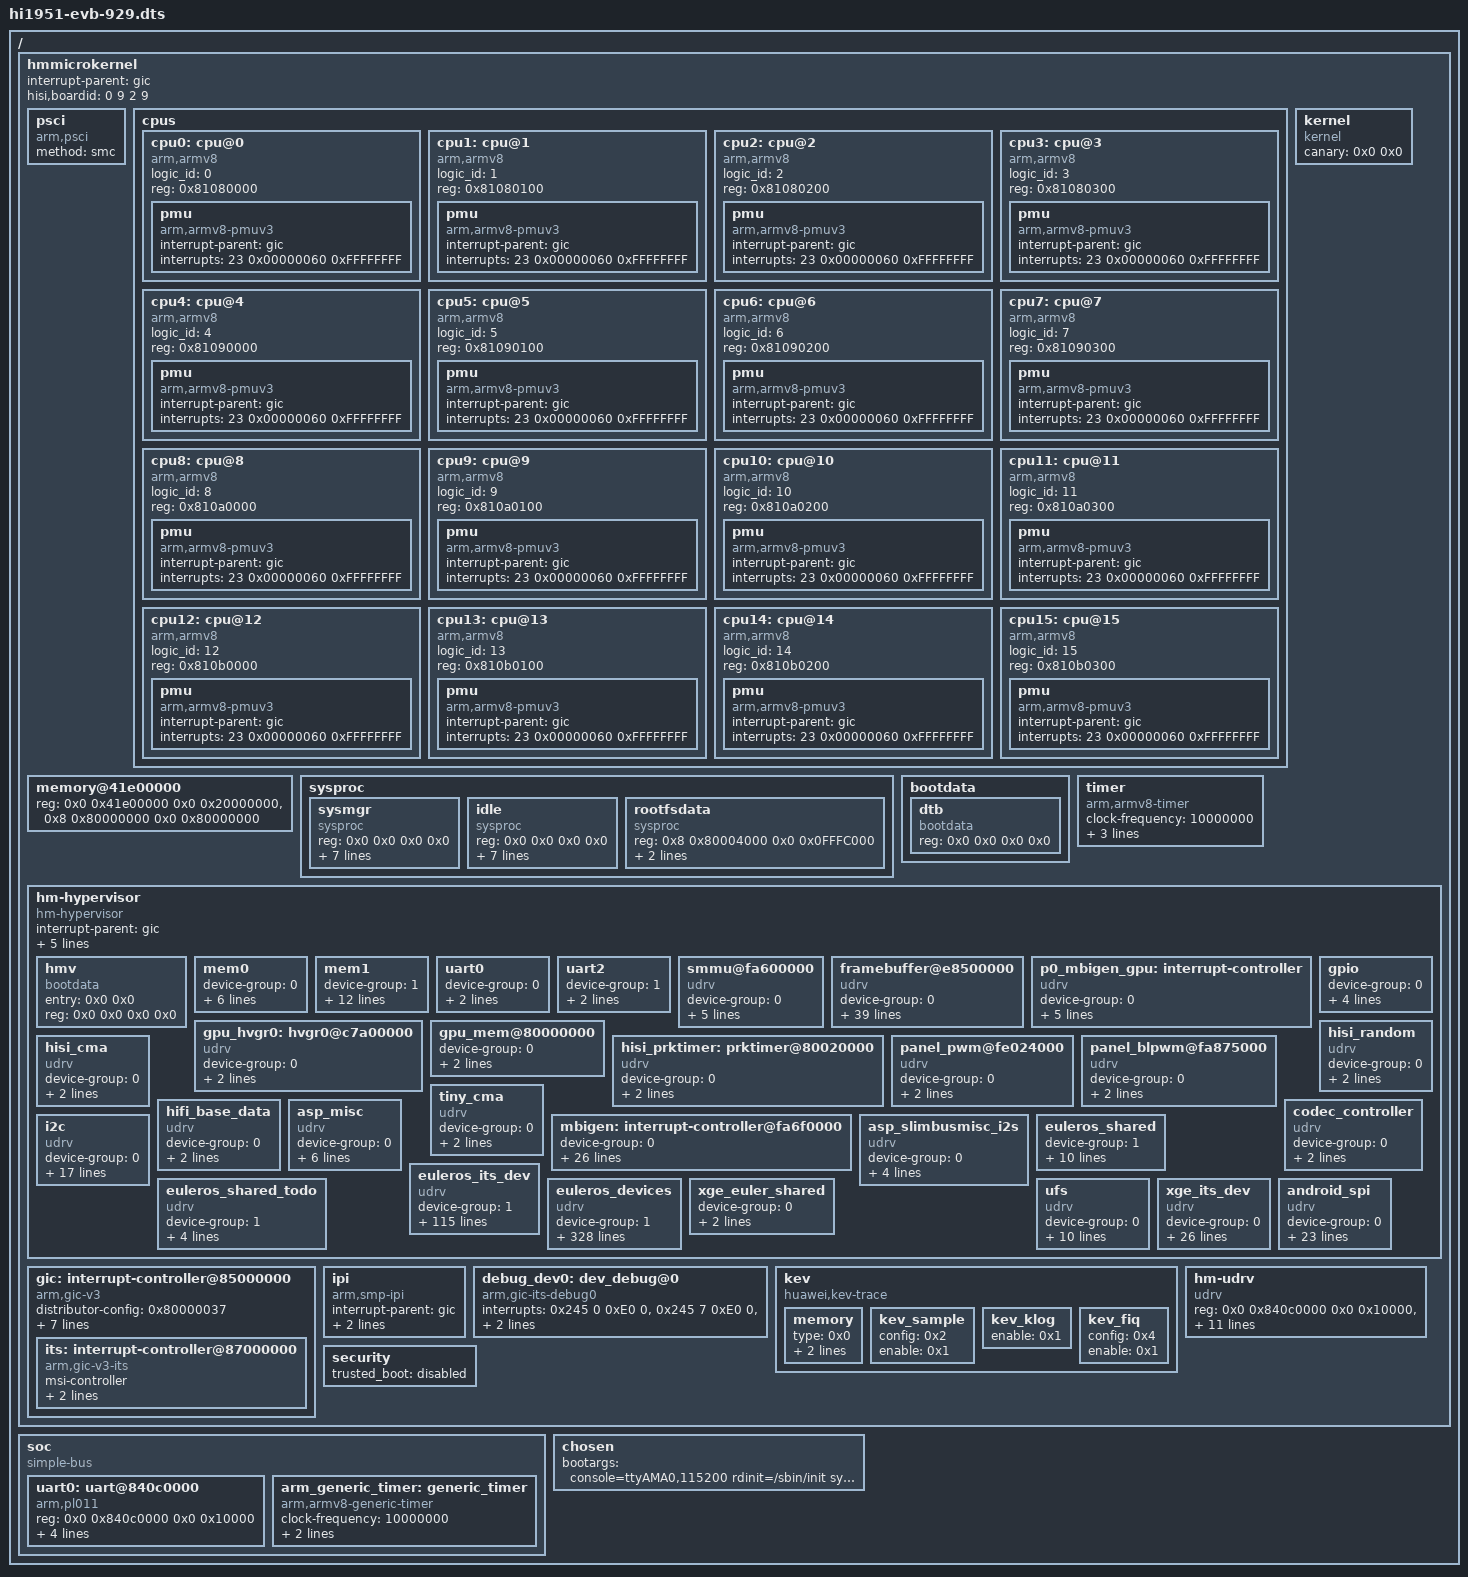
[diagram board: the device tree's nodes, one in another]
/dts-v1/;
/ { #address-cells = <2>; #size-cells = <2>; hmmicrokernel {
	interrupt-parent = <&gic>;
	hisi,boardid = <0 9 2 9>;
	#address-cells = <2>;
	#size-cells = <2>;

	psci {
		compatible = "arm,psci";
		method = "smc";
	};

	cpus {
		#address-cells = <1>;
		#size-cells = <0>;
		cpu0: cpu@0 {
			compatible = "arm,armv8";
			device_type = "cpu";
			logic_id = <0>;
			reg = <0x81080000>;
			pmu {
				compatible = "arm,armv8-pmuv3";
				interrupt-parent = <&gic>;
				/* PPI 23: PMUIRQ, level triggered, hwprio:0x60 */
				interrupts = <23 0x00000060 0xFFFFFFFF>;
			};
		};

		cpu1: cpu@1 {
			compatible = "arm,armv8";
			device_type = "cpu";
			logic_id = <1>;
			reg = <0x81080100>;
			pmu {
				compatible = "arm,armv8-pmuv3";
				interrupt-parent = <&gic>;
				/* PPI 23: PMUIRQ, level triggered, hwprio:0x60 */
				interrupts = <23 0x00000060 0xFFFFFFFF>;
			};
		};

		cpu2: cpu@2 {
			compatible = "arm,armv8";
			device_type = "cpu";
			logic_id = <2>;
			reg = <0x81080200>;
			pmu {
				compatible = "arm,armv8-pmuv3";
				interrupt-parent = <&gic>;
				/* PPI 23: PMUIRQ, level triggered, hwprio:0x60 */
				interrupts = <23 0x00000060 0xFFFFFFFF>;
			};
		};

		cpu3: cpu@3 {
			compatible = "arm,armv8";
			device_type = "cpu";
			logic_id = <3>;
			reg = <0x81080300>;
			pmu {
				compatible = "arm,armv8-pmuv3";
				interrupt-parent = <&gic>;
				/* PPI 23: PMUIRQ, level triggered, hwprio:0x60 */
				interrupts = <23 0x00000060 0xFFFFFFFF>;
			};
		};

		cpu4: cpu@4 {
			compatible = "arm,armv8";
			device_type = "cpu";
			logic_id = <4>;
			reg = <0x81090000>;
			pmu {
				compatible = "arm,armv8-pmuv3";
				interrupt-parent = <&gic>;
				/* PPI 23: PMUIRQ, level triggered, hwprio:0x60 */
				interrupts = <23 0x00000060 0xFFFFFFFF>;
			};
		};

		cpu5: cpu@5 {
			compatible = "arm,armv8";
			device_type = "cpu";
			logic_id = <5>;
			reg = <0x81090100>;
			pmu {
				compatible = "arm,armv8-pmuv3";
				interrupt-parent = <&gic>;
				/* PPI 23: PMUIRQ, level triggered, hwprio:0x60 */
				interrupts = <23 0x00000060 0xFFFFFFFF>;
			};
		};

		cpu6: cpu@6 {
			compatible = "arm,armv8";
			device_type = "cpu";
			logic_id = <6>;
			reg = <0x81090200>;
			pmu {
				compatible = "arm,armv8-pmuv3";
				interrupt-parent = <&gic>;
				/* PPI 23: PMUIRQ, level triggered, hwprio:0x60 */
				interrupts = <23 0x00000060 0xFFFFFFFF>;
			};
		};

		cpu7: cpu@7 {
			compatible = "arm,armv8";
			device_type = "cpu";
			logic_id = <7>;
			reg = <0x81090300>;
			pmu {
				compatible = "arm,armv8-pmuv3";
				interrupt-parent = <&gic>;
				/* PPI 23: PMUIRQ, level triggered, hwprio:0x60 */
				interrupts = <23 0x00000060 0xFFFFFFFF>;
			};
		};

		cpu8: cpu@8 {
			compatible = "arm,armv8";
			device_type = "cpu";
			logic_id = <8>;
			reg = <0x810a0000>;
			pmu {
				compatible = "arm,armv8-pmuv3";
				interrupt-parent = <&gic>;
				/* PPI 23: PMUIRQ, level triggered, hwprio:0x60 */
				interrupts = <23 0x00000060 0xFFFFFFFF>;
			};
		};

		cpu9: cpu@9 {
			compatible = "arm,armv8";
			device_type = "cpu";
			logic_id = <9>;
			reg = <0x810a0100>;
			pmu {
				compatible = "arm,armv8-pmuv3";
				interrupt-parent = <&gic>;
				/* PPI 23: PMUIRQ, level triggered, hwprio:0x60 */
				interrupts = <23 0x00000060 0xFFFFFFFF>;
			};
		};

		cpu10: cpu@10 {
			compatible = "arm,armv8";
			device_type = "cpu";
			logic_id = <10>;
			reg = <0x810a0200>;
			pmu {
				compatible = "arm,armv8-pmuv3";
				interrupt-parent = <&gic>;
				/* PPI 23: PMUIRQ, level triggered, hwprio:0x60 */
				interrupts = <23 0x00000060 0xFFFFFFFF>;
			};
		};

		cpu11: cpu@11 {
			compatible = "arm,armv8";
			device_type = "cpu";
			logic_id = <11>;
			reg = <0x810a0300>;
			pmu {
				compatible = "arm,armv8-pmuv3";
				interrupt-parent = <&gic>;
				/* PPI 23: PMUIRQ, level triggered, hwprio:0x60 */
				interrupts = <23 0x00000060 0xFFFFFFFF>;
			};
		};

		cpu12: cpu@12 {
			compatible = "arm,armv8";
			device_type = "cpu";
			logic_id = <12>;
			reg = <0x810b0000>;
			pmu {
				compatible = "arm,armv8-pmuv3";
				interrupt-parent = <&gic>;
				/* PPI 23: PMUIRQ, level triggered, hwprio:0x60 */
				interrupts = <23 0x00000060 0xFFFFFFFF>;
			};
		};

		cpu13: cpu@13 {
			compatible = "arm,armv8";
			device_type = "cpu";
			logic_id = <13>;
			reg = <0x810b0100>;
			pmu {
				compatible = "arm,armv8-pmuv3";
				interrupt-parent = <&gic>;
				/* PPI 23: PMUIRQ, level triggered, hwprio:0x60 */
				interrupts = <23 0x00000060 0xFFFFFFFF>;
			};
		};

		cpu14: cpu@14 {
			compatible = "arm,armv8";
			device_type = "cpu";
			logic_id = <14>;
			reg = <0x810b0200>;
			pmu {
				compatible = "arm,armv8-pmuv3";
				interrupt-parent = <&gic>;
				/* PPI 23: PMUIRQ, level triggered, hwprio:0x60 */
				interrupts = <23 0x00000060 0xFFFFFFFF>;
			};
		};

		cpu15: cpu@15 {
			compatible = "arm,armv8";
			device_type = "cpu";
			logic_id = <15>;
			reg = <0x810b0300>;
			pmu {
				compatible = "arm,armv8-pmuv3";
				interrupt-parent = <&gic>;
				/* PPI 23: PMUIRQ, level triggered, hwprio:0x60 */
				interrupts = <23 0x00000060 0xFFFFFFFF>;
			};
		};
	};

	memory@41e00000 {
		device_type = "memory";
		reg = <0x0 0x41e00000 0x0 0x20000000>,
		      <0x8 0x80000000 0x0 0x80000000>;
	};

	sysproc {
		#address-cells = <2>;
		#size-cells = <2>;
		sysmgr {
			compatible = "sysproc", "sysmgr";
			/* filled by bootloader */
			reg      = <0x0 0x0 0x0 0x0>;
			vphdr    = <0x0 0x0>;
			ventry   = <0x0 0x0>;
			pvoffset = <0x0 0x0>;
			nphdrs   = <0>;
			stack_start = <0x0 0x0>;
			stack_end = <0x0 0x0>;
			canary = <0x0 0x0>;
		};
		idle {
			compatible = "sysproc", "idle";
			/* filled by bootloader */
			reg      = <0x0 0x0 0x0 0x0>;
			vphdr    = <0x0 0x0>;
			ventry   = <0x0 0x0>;
			pvoffset = <0x0 0x0>;
			nphdrs   = <0>;
			stack_start = <0x0 0x0>;
			stack_end = <0x0 0x0>;
			canary = <0x0 0x0>;
		};

		rootfsdata {
			compatible = "sysproc", "rootfs";
			reg = <0x8 0x80004000 0x0 0x0FFFC000>;
			ventry = <0x0 0x0>;
			/* filled by bootloader */
			pvoffset = <0x0 0x0>;
		};
	};

	kernel {
		compatible = "kernel";
		/* filled by bootloader */
		canary = <0x0 0x0>;
	};

	bootdata {
		#address-cells = <2>;
		#size-cells = <2>;
		dtb {
			compatible = "bootdata", "dtb";
			/* filled by bootloader */
			reg = <0x0 0x0 0x0 0x0>;
		};
	};

	timer {
		compatible = "arm,armv8-timer";
		clock-frequency = <10000000>;
		/* interrupt settings */
		interrupt-parent = <&gic>;

		/* PPI 30: Non-secure physical timer
		 * level triggered, only cpu0, hwprio:0x60 */
		interrupts = <30 0x00000060 0xFFFFFFFF>,
			     <26 0x00000060 0xFFFFFFFF>;
	};

	hm-hypervisor {
		compatible = "hm-hypervisor";
		#address-cells = <2>;
		#size-cells = <2>;

		interrupt-parent = <&gic>;
		interrupts = <15 0x00000060 0xFFFFFFFF>,
			     <25 0x00000060 0xFFFFFFFF>,
			     <27 0x00000060 0xFFFFFFFF>;

		virtual-timer-irq = <27>;
		vgic-base-address = <0x7F 0xFF000000>;

		hmv {
			compatible = "bootdata";
			/* filled by bootloader */
			entry = <0x0 0x0>;
			reg = <0x0 0x0 0x0 0x0>;
		};

		mem0 {
			device-group = <0>;
			normal-mem;
			uvmm-access;
			reg = <0x9 0x00000000 0x0 0x0FFF0000>,
			      <0x9 0x10000000 0x0 0x6C000000>;
			map = <0x0 0x00000000 0x0 0x0FFF0000>,
			      <0x9 0x10000000 0x0 0x6C000000>;
		};

		mem1 {
			device-group = <1>;
			normal-mem;
			uvmm-access;
			reg = <0xA 0x00000000 0x0 0x0FFF0000>,
			      <0xA 0x10000000 0x1 0xf0000000>,
			      <0x0 0x0B101000 0x0 0x001FF000>, //log_redirect
			      <0x0 0x61E00000 0x0 0x10000000>, //cma GPA: 0x6bc00000
			      <0x9 0x10000000 0x0 0x6C000000>;
			map = <0xA 0x00000000 0x0 0x0FFF0000>,
			      <0xA 0x10000000 0x1 0xf0000000>,
			      <0x0 0x0B101000 0x0 0x001FF000>, //log_redirect
			      <0x0 0x61E00000 0x0 0x10000000>, //cma GPA: 0x6bc00000
			      <0x9 0x10000000 0x0 0x6C000000>;
		};

		uart0 {
			device-group = <0>;
			reg = <0x00 0x840c0000 0x0 0x00010000>;
			map = <0x7F 0xFE000000 0x0 0x00010000>;
		};

		uart2 {
			device-group = <1>;
			reg = <0x00 0x840c0000 0x0 0x00010000>;
			map = <0x7F 0xFE000000 0x0 0x00010000>;
		};

		smmu@fa600000 {
			device-group = <0>;
			compatible = "udrv";
			msi-parent = <&its>;
			interrupts = <0x7f41 0 0xE0 0>,
				     <0x7f41 1 0xE0 0>,
				     <0x7f41 2 0xE0 0>,
				     <0x7f41 3 0xE0 0>;
			reg = <0x0 0xfa600000 0x0 0x40000>;
			map = <0x0 0xfa600000 0x0 0x40000>;
		};

		framebuffer@e8500000 {
			device-group = <0>;
			compatible = "udrv";
			interrupt-parent = <&gic>;
			interrupts = <277 0x000000E0 0xFFFFFFFF>,
				     <278 0x000000E0 0xFFFFFFFF>,
				     <279 0x000000E0 0xFFFFFFFF>,
				     <283 0x000000E0 0xFFFFFFFF>,
				     <284 0x000000E0 0xFFFFFFFF>,
				     <363 0x000000E0 0xFFFFFFFF>,
				     <319 0x000000E0 0xFFFFFFFF>,
				     <388 0x000000E0 0xFFFFFFFF>,
				     <316 0x000000E0 0xFFFFFFFF>,
				     <317 0x000000E0 0xFFFFFFFF>,
				     <318 0x000000E0 0xFFFFFFFF>,
				     <322 0x000000E0 0xFFFFFFFF>;
			reg = <0x0 0xe8500000 0x0 0x000a0000>,
			      <0x0 0xe8601000 0x0 0x00001000>,
			      <0x0 0xe8680000 0x0 0x00010000>,
			      <0x0 0xe8820000 0x0 0x00001000>,
			      <0x0 0xf8481000 0x0 0x00001000>,
			      <0x0 0xf8500000 0x0 0x00080000>,
			      <0x0 0xf8581000 0x0 0x00001000>,
			      <0x0 0xfa670000 0x0 0x00010000>,
			      <0x0 0xfa700000 0x0 0x00100000>,
			      <0x0 0xfa89b000 0x0 0x00001000>,
			      <0x0 0xffa2e000 0x0 0x00001000>,
			      <0x0 0xfff01000 0x0 0x00001000>,
			      <0x0 0xfff05000 0x0 0x00001000>;
			map = <0x0 0xe8500000 0x0 0x000a0000>,
			      <0x0 0xe8601000 0x0 0x00001000>,
			      <0x0 0xe8680000 0x0 0x00010000>,
			      <0x0 0xe8820000 0x0 0x00001000>,
			      <0x0 0xf8481000 0x0 0x00001000>,
			      <0x0 0xf8500000 0x0 0x00080000>,
			      <0x0 0xf8581000 0x0 0x00001000>,
			      <0x0 0xfa670000 0x0 0x00010000>,
			      <0x0 0xfa700000 0x0 0x00100000>,
			      <0x0 0xfa89b000 0x0 0x00001000>,
			      <0x0 0xffa2e000 0x0 0x00001000>,
			      <0x0 0xfff01000 0x0 0x00001000>,
			      <0x0 0xfff05000 0x0 0x00001000>;
		};

		p0_mbigen_gpu: interrupt-controller {
			device-group = <0>;
			compatible = "udrv";
			msi-parent = <&its>;
			interrupts = <0x7f94 0 0xE0 0>,
				     <0x7f94 1 0xE0 0>,
				     <0x7f94 2 0xE0 0>,
				     <0x7f94 3 0xE0 0>;
			reg = <0x0 0xc7800000 0x0 0x100000>;
			map = <0x0 0xc7800000 0x0 0x100000>;
		};

		gpu_hvgr0: hvgr0@c7a00000 {
			device-group = <0>;
			compatible = "udrv";
			reg = <0x0 0xc7a00000 0x0 0x10000>;
			map = <0x0 0xc7a00000 0x0 0x10000>;
		};

		gpu_mem@80000000 {
			device-group = <0>;
			reg = <0x0 0x80000000 0x0 0x10000>;
			map = <0x0 0x80000000 0x0 0x10000>;
		};

		hisi_prktimer: prktimer@80020000 {
			device-group = <0>;
			compatible = "udrv";
			reg = <0x0 0x80020000 0x0 0x10000>;
			map = <0x0 0x80020000 0x0 0x10000>;
		};

		panel_pwm@fe024000 {
			device-group = <0>;
			compatible = "udrv";
			reg = <0x0 0xfe024000 0x0 0x1000>;
			map = <0x0 0xfe024000 0x0 0x1000>;
		};

		panel_blpwm@fa875000 {
			device-group = <0>;
			compatible = "udrv";
			reg = <0x0 0xfa875000 0x0 0x1000>;
			map = <0x0 0xfa875000 0x0 0x1000>;
		};

		gpio {
			device-group = <0>;
			reg = <0x0 0xfa6b0000 0x0 0x10000>,
			      <0x0 0x840f0000 0x0 0x10000>;
			map = <0x0 0xfa6b0000 0x0 0x10000>,
			      <0x0 0x840f0000 0x0 0x10000>;
		};

		hisi_random {
			device-group = <0>;
			compatible = "udrv";
			reg = <0x0 0x11593000 0x0 0x01000>;
			map = <0x0 0x11593000 0x0 0x01000>;
		};

		hisi_cma {
			device-group = <0>;
			compatible = "udrv";
			reg = <0x9 0x90000000 0x0 0x10000000>;
			map = <0x0 0x61E00000 0x0 0x10000000>;
		};

		tiny_cma {
			device-group = <0>;
			compatible = "udrv";
			reg = <0x9 0xa0000000 0x0 0x04000000>;
			map = <0x0 0x71E00000 0x0 0x04000000>;
		};

		hifi_base_data: hifi_base_data {
			device-group = <0>;
			compatible = "udrv";
			reg = <0x0 0x29800000 0x0 0x01500000>;
			map = <0x0 0x29800000 0x0 0x01500000>;
		};

		mbigen: interrupt-controller@fa6f0000 {
			device-group = <0>;
			msi-parent = <&its>;
			interrupts = <0x7f80 0 0xE0 0>, <0x7f80 1 0xE0 0>,
				     <0x7f80 2 0xE0 0>, <0x7f80 3 0xE0 0>,
				     <0x7f80 4 0xE0 0>, <0x7f80 5 0xE0 0>,
				     <0x7f81 0 0xE0 0>, <0x7f81 1 0xE0 0>,
				     <0x7f82 0 0xE0 0>, <0x7f82 1 0xE0 0>,
				     <0x7f83 0 0xE0 0>, <0x7f83 1 0xE0 0>,
				     <0x7f90 0 0xE0 0>, <0x7f90 1 0xE0 0>,
				     <0x7f90 2 0xE0 0>, <0x7f90 3 0xE0 0>,
				     <0x7f90 4 0xE0 0>, <0x7f90 5 0xE0 0>,
				     <0x7f90 6 0xE0 0>, <0x7f90 7 0xE0 0>,
				     <0x7f90 8 0xE0 0>, <0x7f90 9 0xE0 0>,
				     <0x7f90 10 0xE0 0>, <0x7f90 11 0xE0 0>,
				     <0x7f90 12 0xE0 0>, <0x7f90 13 0xE0 0>,
				     <0x7f90 14 0xE0 0>, <0x7f90 15 0xE0 0>,
				     <0x7f90 16 0xE0 0>, <0x7f90 17 0xE0 0>,
				     <0x7f90 18 0xE0 0>, <0x7f90 19 0xE0 0>,
				     <0x7f90 20 0xE0 0>, <0x7f90 21 0xE0 0>,
				     <0x7f90 22 0xE0 0>, <0x7f90 23 0xE0 0>,
				     <0x7f90 24 0xE0 0>, <0x7f90 25 0xE0 0>,
				     <0x7f90 26 0xE0 0>, <0x7f90 27 0xE0 0>,
				     <0x7f90 28 0xE0 0>, <0x7f90 29 0xE0 0>,
				     <0x7f90 30 0xE0 0>, <0x7f90 31 0xE0 0>,
				     <0x7fab 32 0xE0 0>, <0x7fab 33 0xE0 0>;
			reg = <0x0 0xfa6f0000 0x0 0x10000>;
			map = <0x0 0xfa6f0000 0x0 0x10000>;
		};

		codec_controller: codec_controller {
			device-group = <0>;
			compatible = "udrv";
			reg = <0x0 0xffb04000 0x0 0x1000>;
			map = <0x0 0xffb04000 0x0 0x1000>;
		};

		asp_misc: asp_misc {
			device-group = <0>;
			compatible = "udrv";
			reg = <0x0 0xfa680000 0x0 0x7000>,
			      <0x0 0xfa6c0000 0x0 0x10000>,
			      <0x0 0xfa660000 0x0 0x4000>;
			map = <0x0 0xfa680000 0x0 0x7000>,
			      <0x0 0xfa6c0000 0x0 0x10000>,
			      <0x0 0xfa660000 0x0 0x4000>;
		};

		asp_slimbusmisc_i2s: asp_slimbusmisc_i2s {
			device-group = <0>;
			compatible = "udrv";
			interrupt-parent = <&gic>;
			interrupts = <182 0x000000E0 0xFFFFFFFF>;
			reg = <0x0 0xfa400000 0x0 0x1c0000>;
			map = <0x0 0xfa400000 0x0 0x1c0000>;
		};

		i2c {
			device-group = <0>;
			compatible = "udrv";
			interrupt-parent = <&gic>;
			interrupts = < 88 0x000000E0 0xFFFFFFFF>,
				     <218 0x000000E0 0xFFFFFFFF>,
				     <219 0x000000E0 0xFFFFFFFF>,
				     <220 0x000000E0 0xFFFFFFFF>,
				     <288 0x000000E0 0xFFFFFFFF>,
				     <289 0x000000E0 0xFFFFFFFF>,
				     <361 0x000000E0 0xFFFFFFFF>,
				     < 85 0x000000E0 0xFFFFFFFF>;
			reg = <0x0 0x8b0c0000 0x0 0x10000>,
			      <0x0 0x84040000 0x0 0x40000>,
			      <0x0 0xa2180000 0x0 0x20000>,
			      <0x0 0xfa690000 0x0 0x10000>;
			map = <0x0 0x8b0c0000 0x0 0x10000>,
			      <0x0 0x84040000 0x0 0x40000>,
			      <0x0 0xa2180000 0x0 0x20000>,
			      <0x0 0xfa690000 0x0 0x10000>;
		};

		euleros_shared {
			device-group = <1>;
			reg = <0x0 0x80000000 0x0 0x00010000>, //rdr_ap_adapter rdr_spmi mttcan2 mttcan3 mttcan4
			      <0x0 0xa4510000 0x0 0x00001000>, //udrv gpio1
			      <0x0 0x840f0000 0x0 0x00010000>, //gpio
			      <0x0 0xfa6b0000 0x0 0x00010000>, //gpio3
			      <0x0 0xfa6f0000 0x0 0x00010000>; //mbigen
			map = <0x0 0x80000000 0x0 0x00010000>, //rdr_ap_adapter rdr_spmi mttcan2 mttcan3 mttcan4
			      <0x0 0xa4510000 0x0 0x00001000>, //udrv gpio1
			      <0x0 0x840f0000 0x0 0x00010000>, //gpio
			      <0x0 0xfa6b0000 0x0 0x00010000>, //gpio3
			      <0x0 0xfa6f0000 0x0 0x00010000>; //mbigen
		};

		euleros_shared_todo {
			device-group = <1>;
			compatible = "udrv";
			reg = <0xc 0x00000000 0x0 0x20000000>, //runtime test case
			      <0xc 0x60000000 0x0 0x40000000>; //acl test case
			map = <0xc 0x00000000 0x0 0x20000000>, //runtime test case
			      <0xc 0x60000000 0x0 0x40000000>; //acl test case
		};

		euleros_its_dev {
			device-group = <1>;
			compatible = "udrv";
			msi-parent = <&its>;

			interrupts =	<0x7400 0xff 0xE0 0>,//pcie
					<0x7b00 0x00 0xE0 0>,//pcie dma
					<0x7b00 0x1f 0xE0 0>,//pcie dma
					<0x7b08 0x00 0xE0 0>,//doorbell
					<0x7b08 0x1c 0xE0 0>,//doorbell
					<0x7f1b 0x00 0xE0 0>,//mmu
					<0x7f1b 0xff 0xE0 0>,//mmu
					<0x7f20 0x00 0xE0 0>,//925 peri_smmu
					<0x7f20 0x01 0xE0 0>,//dvpp
					<0x7f21 0x00 0xE0 0>,//dvpp
					<0x7f21 0x01 0xE0 0>,//dvpp
					<0x7f22 0x00 0xE0 0>,//dvpp
					<0x7f22 0x01 0xE0 0>,//dvpp
					<0x7f23 0x00 0xE0 0>,//dvpp/dsmmu0
					<0x7f23 0x01 0xE0 0>,//dvpp/dsmmu0
					<0x7f24 0x00 0xE0 0>,//dvpp
					<0x7f24 0x01 0xE0 0>,//dvpp
					<0x7f25 0x00 0xE0 0>,//dvpp
					<0x7f25 0x01 0xE0 0>,//dvpp
					<0x7f26 0x00 0xE0 0>,//mmu
					<0x7f26 0x01 0xE0 0>,//mmu
					<0x7f27 0x00 0xE0 0>,//mmu
					<0x7f27 0x01 0xE0 0>,//mmu
					<0x7f28 0x00 0xE0 0>,//mmu
					<0x7f28 0x01 0xE0 0>,//mmu
					<0x7f29 0x00 0xE0 0>,//mmu
					<0x7f29 0x01 0xE0 0>,//mmu
					<0x7f2a 0x00 0xE0 0>,//mmu
					<0x7f2a 0x01 0xE0 0>,//mmu
					<0x7f2b 0x00 0xE0 0>,//mmu
					<0x7f2b 0x01 0xE0 0>,//mmu
					<0x7f2c 0x00 0xE0 0>,//mmu
					<0x7f2c 0x01 0xE0 0>,//mmu
					<0x7f2d 0x00 0xE0 0>,//mmu
					<0x7f2d 0x01 0xE0 0>,//mmu
					<0x7f2e 0x00 0xE0 0>,//mmu
					<0x7f2e 0x01 0xE0 0>,//mmu
					<0x7f2f 0x00 0xE0 0>,//mmu
					<0x7f2f 0x01 0xE0 0>,//mmu
					<0x7f30 0x00 0xE0 0>,//mmu
					<0x7f30 0x01 0xE0 0>,//mmu
					<0x7f31 0x00 0xE0 0>,//mmu
					<0x7f31 0x01 0xE0 0>,//mmu
					<0x7f38 0x00 0xE0 0>,//mmu
					<0x7f38 0x01 0xE0 0>,//mmu
					<0x7f39 0x00 0xE0 0>,//mmu
					<0x7f39 0x01 0xE0 0>,//mmu
					<0x7f3a 0x00 0xE0 0>,//mmu
					<0x7f3a 0x01 0xE0 0>,//mmu
					<0x7f3b 0x00 0xE0 0>,//mmu
					<0x7f3b 0x01 0xE0 0>,//mmu
					<0x7f3c 0x00 0xE0 0>,//mmu
					<0x7f3c 0x01 0xE0 0>,//mmu
					<0x7f3d 0x00 0xE0 0>,//mmu
					<0x7f3d 0x01 0xE0 0>,//mmu
					<0x7f3e 0x00 0xE0 0>,//mmu
					<0x7f3e 0x01 0xE0 0>,//mmu
					<0x7f3f 0x00 0xE0 0>,//mmu
					<0x7f3f 0x01 0xE0 0>,//mmu
					<0x7f40 0x00 0xE0 0>,//mmu
					<0x7f40 0x01 0xE0 0>,//mmu
					<0x7f45 0x00 0xE0 0>,//mmu
					<0x7f45 0xff 0xE0 0>,//mmu
					<0x7f46 0x00 0xE0 0>,//mmu
					<0x7f46 0x01 0xE0 0>,//mmu
					<0x7f49 0x00 0xE0 0>,//dvpp_smmu0
					<0x7f49 0x01 0xE0 0>,//dvpp_smmu0
					<0x7f58 0x00 0xE0 0>,//mbigen_vdec
					<0x7f58 0xff 0xE0 0>,//mbigen_vdec
					<0x7f5d 0x00 0xE0 0>,//mbigen_jpegd
					<0x7f5d 0xff 0xE0 0>,//mbigen_jpegd
					<0x7f5f 0x00 0xE0 0>,//mbigen_jpege
					<0x7f5f 0xff 0xE0 0>,//mbigen_jpege
					<0x7f77 0x00 0xE0 0>,//mbigen_vpc_err
					<0x7f77 0xff 0xE0 0>,//mbigen_vpc_err
					<0x7f91 0xff 0xE0 0>,//dvpp
					<0x7f96 0x00 0xE0 0>,//mbigen_gpio5
					<0x7f96 0x01 0xE0 0>,//mbigen_gpio5
					<0x7f96 0x02 0xE0 0>,//mbigen_gpio5
					<0x7f96 0x03 0xE0 0>,//mbigen_gpio5
					<0x7f96 0x04 0xE0 0>,//mbigen_gpio5
					<0x7f96 0x05 0xE0 0>,//mbigen_gpio5
					<0x7f96 0x06 0xE0 0>,//mbigen_gpio5
					<0x7f96 0x07 0xE0 0>,//mbigen_gpio5
					<0x7f96 0x08 0xE0 0>,//mbigen_gpio5
					<0x7f96 0x09 0xE0 0>,//mbigen_gpio5
					<0x7f96 0x0a 0xE0 0>,//mbigen_gpio5
					<0x7f96 0x0b 0xE0 0>,//mbigen_gpio5
					<0x7f96 0x0c 0xE0 0>,//mbigen_gpio5
					<0x7f96 0x0d 0xE0 0>,//mbigen_gpio5
					<0x7f96 0x0e 0xE0 0>,//mbigen_gpio5
					<0x7f96 0x0f 0xE0 0>,//mbigen_gpio5
					<0x7f96 0x10 0xE0 0>,//mbigen_gpio5
					<0x7f96 0x11 0xE0 0>,//mbigen_gpio5
					<0x7f96 0x12 0xE0 0>,//mbigen_gpio5
					<0x7f96 0x13 0xE0 0>,//mbigen_gpio5
					<0x7f96 0x14 0xE0 0>,//mbigen_gpio5
					<0x7f96 0x15 0xE0 0>,//mbigen_gpio5
					<0x7f96 0x16 0xE0 0>,//mbigen_gpio5
					<0x7f96 0x17 0xE0 0>,//mbigen_gpio5
					<0x7f96 0x18 0xE0 0>,//mbigen_gpio5
					<0x7f96 0x19 0xE0 0>,//mbigen_gpio5
					<0x7f96 0x1a 0xE0 0>,//mbigen_gpio5
					<0x7f96 0x1b 0xE0 0>,//mbigen_gpio5
					<0x7f96 0x1c 0xE0 0>,//mbigen_gpio5
					<0x7f96 0x1d 0xE0 0>,//mbigen_gpio5
					<0x7f96 0x1e 0xE0 0>,//mbigen_gpio5
					<0x7f96 0x1f 0xE0 0>,//mbigen_gpio5
					<0x7f96 0xff 0xE0 0>,//mbigen_gpio5
					<0x7f9e 0x00 0xE0 0>,//mbigen_gpio4
					<0x7f9e 0x01 0xE0 0>,//mbigen_gpio4
					<0x7f9e 0x02 0xE0 0>,//mbigen_gpio4
					<0x7f9e 0x03 0xE0 0>,//mbigen_gpio4
					<0x7f9e 0x04 0xE0 0>,//mbigen_gpio4
					<0x7f9e 0x05 0xE0 0>,//mbigen_gpio4
					<0x7f9e 0x06 0xE0 0>,//mbigen_gpio4
					<0x7f9e 0x07 0xE0 0>,//mbigen_gpio4
					<0x7f9e 0x08 0xE0 0>,//mbigen_gpio4
					<0x7f9e 0x09 0xE0 0>,//mbigen_gpio4
					<0x7f9e 0x0a 0xE0 0>,//mbigen_gpio4
					<0x7f9e 0x0b 0xE0 0>,//mbigen_gpio4
					<0x7f9e 0x0c 0xE0 0>,//mbigen_gpio4
					<0x7f9e 0x0d 0xE0 0>,//mbigen_gpio4
					<0x7f9e 0x0e 0xE0 0>,//mbigen_gpio4
					<0x7f9e 0x0f 0xE0 0>,//mbigen_gpio4
					<0x7f9e 0x10 0xE0 0>,//mbigen_gpio4
					<0x7f9e 0x11 0xE0 0>,//mbigen_gpio4
					<0x7f9e 0x12 0xE0 0>,//mbigen_gpio4
					<0x7f9e 0x13 0xE0 0>,//mbigen_gpio4
					<0x7f9e 0x14 0xE0 0>,//mbigen_gpio4
					<0x7f9e 0x15 0xE0 0>,//mbigen_gpio4
					<0x7f9e 0x16 0xE0 0>,//mbigen_gpio4
					<0x7f9e 0x17 0xE0 0>,//mbigen_gpio4
					<0x7f9e 0x18 0xE0 0>,//mbigen_gpio4
					<0x7f9e 0x19 0xE0 0>,//mbigen_gpio4
					<0x7f9e 0x1a 0xE0 0>,//mbigen_gpio4
					<0x7f9e 0x1b 0xE0 0>,//mbigen_gpio4
					<0x7f9e 0x1c 0xE0 0>,//mbigen_gpio4
					<0x7f9e 0x1d 0xE0 0>,//mbigen_gpio4
					<0x7f9e 0x1e 0xE0 0>,//mbigen_gpio4
					<0x7f9e 0x1f 0xE0 0>,//mbigen_gpio4
					<0x7f9e 0xff 0xE0 0>,//mbigen_gpio4
					<0x7faa 0x00 0xE0 0>,//mbigen_gpio7
					<0x7faa 0x01 0xE0 0>,//mbigen_gpio7
					<0x7faa 0x02 0xE0 0>,//mbigen_gpio7
					<0x7faa 0x03 0xE0 0>,//mbigen_gpio7
					<0x7faa 0x04 0xE0 0>,//mbigen_gpio7
					<0x7faa 0x05 0xE0 0>,//mbigen_gpio7
					<0x7faa 0x06 0xE0 0>,//mbigen_gpio7
					<0x7faa 0x07 0xE0 0>,//mbigen_gpio7
					<0x7fa4 0x00 0xE0 0>,//mbigen_gpio0
					<0x7fa4 0x01 0xE0 0>,//mbigen_gpio0
					<0x7fa4 0x02 0xE0 0>,//mbigen_gpio0
					<0x7fa4 0x03 0xE0 0>,//mbigen_gpio0
					<0x7fa4 0x04 0xE0 0>,//mbigen_gpio0
					<0x7fa4 0x05 0xE0 0>,//mbigen_gpio0
					<0x7fa4 0x06 0xE0 0>,//mbigen_gpio0
					<0x7fa4 0x07 0xE0 0>,//mbigen_gpio0
					<0x7fa4 0x08 0xE0 0>,//mbigen_gpio0
					<0x7fa4 0x09 0xE0 0>,//mbigen_gpio0
					<0x7fa4 0x0a 0xE0 0>,//mbigen_gpio0
					<0x7fa4 0x0b 0xE0 0>,//mbigen_gpio0
					<0x7fa4 0x0c 0xE0 0>,//mbigen_gpio0
					<0x7fa4 0x0d 0xE0 0>,//mbigen_gpio0
					<0x7fa4 0x0e 0xE0 0>,//mbigen_gpio0
					<0x7fa4 0x0f 0xE0 0>,//mbigen_gpio0
					<0x7fa4 0x10 0xE0 0>,//mbigen_gpio0
					<0x7fa4 0x11 0xE0 0>,//mbigen_gpio0
					<0x7fa4 0x12 0xE0 0>,//mbigen_gpio0
					<0x7fa4 0x13 0xE0 0>,//mbigen_gpio0
					<0x7fa4 0x14 0xE0 0>,//mbigen_gpio0
					<0x7fa4 0x15 0xE0 0>,//mbigen_gpio0
					<0x7fa4 0x16 0xE0 0>,//mbigen_gpio0
					<0x7fa4 0x17 0xE0 0>,//mbigen_gpio0
					<0x7fa4 0x18 0xE0 0>,//mbigen_gpio0
					<0x7fa4 0x19 0xE0 0>,//mbigen_gpio0
					<0x7fa4 0x1a 0xE0 0>,//mbigen_gpio0
					<0x7fa4 0x1b 0xE0 0>,//mbigen_gpio0
					<0x7fa4 0x1c 0xE0 0>,//mbigen_gpio0
					<0x7fa4 0x1d 0xE0 0>,//mbigen_gpio0
					<0x7fa4 0x1e 0xE0 0>,//mbigen_gpio0
					<0x7fa4 0x1f 0xE0 0>,//mbigen_gpio0
					<0x7fa4 0xff 0xE0 0>,//mbigen_gpio0
					<0x7fa5 0x00 0xE0 0>,//mbigen_gpio1
					<0x7fa5 0x01 0xE0 0>,//mbigen_gpio1
					<0x7fa5 0x02 0xE0 0>,//mbigen_gpio1
					<0x7fa5 0x03 0xE0 0>,//mbigen_gpio1
					<0x7fa5 0x04 0xE0 0>,//mbigen_gpio1
					<0x7fa5 0x05 0xE0 0>,//mbigen_gpio1
					<0x7fa5 0x06 0xE0 0>,//mbigen_gpio1
					<0x7fa5 0x07 0xE0 0>,//mbigen_gpio1
					<0x7fa5 0x08 0xE0 0>,//mbigen_gpio1
					<0x7fa5 0x09 0xE0 0>,//mbigen_gpio1
					<0x7fa5 0x0a 0xE0 0>,//mbigen_gpio1
					<0x7fa5 0x0b 0xE0 0>,//mbigen_gpio1
					<0x7fa5 0x0c 0xE0 0>,//mbigen_gpio1
					<0x7fa5 0x0d 0xE0 0>,//mbigen_gpio1
					<0x7fa5 0x0e 0xE0 0>,//mbigen_gpio1
					<0x7fa5 0x0f 0xE0 0>,//mbigen_gpio1
					<0x7fa5 0x10 0xE0 0>,//mbigen_gpio1
					<0x7fa5 0x11 0xE0 0>,//mbigen_gpio1
					<0x7fa5 0x12 0xE0 0>,//mbigen_gpio1
					<0x7fa5 0x13 0xE0 0>,//mbigen_gpio1
					<0x7fa5 0x14 0xE0 0>,//mbigen_gpio1
					<0x7fa5 0x15 0xE0 0>,//mbigen_gpio1
					<0x7fa5 0x16 0xE0 0>,//mbigen_gpio1
					<0x7fa5 0x17 0xE0 0>,//mbigen_gpio1
					<0x7fa5 0x18 0xE0 0>,//mbigen_gpio1
					<0x7fa5 0x19 0xE0 0>,//mbigen_gpio1
					<0x7fa5 0x1a 0xE0 0>,//mbigen_gpio1
					<0x7fa5 0x1b 0xE0 0>,//mbigen_gpio1
					<0x7fa5 0x1c 0xE0 0>,//mbigen_gpio1
					<0x7fa5 0x1d 0xE0 0>,//mbigen_gpio1
					<0x7fa5 0x1e 0xE0 0>,//mbigen_gpio1
					<0x7fa5 0x1f 0xE0 0>,//mbigen_gpio1
					<0x7fa5 0xff 0xE0 0>,//mbigen_gpio1
					<0x7fa6 0x00 0xE0 0>,//mbigen_gpio2
					<0x7fa6 0x01 0xE0 0>,//mbigen_gpio2
					<0x7fa6 0x02 0xE0 0>;//mbigen_gpio2

			reg =	<0x2 0x01080000 0x0 0x00010000>, //drv_pcie
				<0x0 0xc6f10000 0x0 0x00010000>; //drv_pcie
			map =	<0x2 0x01080000 0x0 0x00010000>, //drv_pcie
				<0x0 0xc6f10000 0x0 0x00010000>; //drv_pcie
		};

		euleros_devices {
			device-group = <1>;
			compatible = "udrv";
			interrupt-parent = <&gic>;

			reg =	<0x1 0x100C0000 0x0 0x00010000>, //mntn rdr & devdrv
				<0x1 0x02060000 0x0 0x00010000>, //devdrv Dispatch
				<0x1 0x000E0000 0x0 0x00010000>, //devdrv FW
				<0x1 0x000a0000 0x0 0x00010000>, //dvpp_controler & devdrv MN
				<0x0 0xd7b00000 0x0 0x00100000>, //pcie
				<0x0 0xd7400000 0x0 0x00400000>, //pcie
				<0x0 0xcf090000 0x0 0x0000B000>, //ipc0
				<0x0 0xc9850000 0x0 0x00010000>, //dvpp_controller
				<0x0 0xc9800000 0x0 0x00040000>, //dvpp_controller
				<0x0 0xc9400000 0x0 0x00100000>, //dvpp venc0
				<0x0 0xc92ca000 0x0 0x00001000>, //dvpp jpegd0
				<0x0 0xc92c8000 0x0 0x00001000>, //dvpp jpege0
				<0x0 0xc92c2000 0x0 0x00002000>, //dvpp jpege0 jpegd0
				<0x0 0xc92c0000 0x0 0x00001000>, //dvpp jpege0 jpegd0
				<0x0 0xc9200000 0x0 0x00040000>, //dvpp vpc0 vpc-err
				<0x0 0xc9180000 0x0 0x00020000>, //dvpp vdec0
				<0x0 0xc90c0000 0x0 0x00010000>, //dvpp_controller
				<0x0 0xc9050000 0x0 0x00010000>, //dvpp_controller
				<0x0 0xc9000000 0x0 0x00040000>, //dvpp dsmmu0
				<0x0 0xc3300000 0x0 0x00040000>, //smmu smmu_ai9
				<0x0 0xc3100000 0x0 0x00040000>, //smmu smmu_ai8
				<0x0 0xc2f00000 0x0 0x00040000>, //smmu smmu_ai7
				<0x0 0xc2d00000 0x0 0x00040000>, //smmu smmu_ai6
				<0x0 0xc2b00000 0x0 0x00040000>, //smmu smmu_ai5
				<0x0 0xc2900000 0x0 0x00040000>, //smmu smmu_ai4
				<0x0 0xc2700000 0x0 0x00040000>, //smmu smmu_ai3
				<0x0 0xc2500000 0x0 0x00040000>, //smmu smmu_ai2
				<0x0 0xc2300000 0x0 0x00040000>, //smmu smmu_ai1
				<0x0 0xc2100000 0x0 0x00040000>, //smmu smmu_ai0
				<0x0 0xc1f00000 0x0 0x00040000>, //smmu smmu_aive7
				<0x0 0xc1d00000 0x0 0x00040000>, //smmu smmu_aive6
				<0x0 0xc1b00000 0x0 0x00040000>, //smmu smmu_aive5
				<0x0 0xc1900000 0x0 0x00040000>, //smmu smmu_aive4
				<0x0 0xc1700000 0x0 0x00040000>, //smmu smmu_aive3
				<0x0 0xc1500000 0x0 0x00040000>, //smmu smmu_aive2
				<0x0 0xc1300000 0x0 0x00040000>, //smmu smmu_aive1
				<0x0 0xc1100000 0x0 0x00040000>, //smmu smmu_aive0
				<0x0 0xbb000000 0x0 0x00040000>,
				<0x0 0xbac00000 0x0 0x00400000>, //ts0_doorbell_paddr
				<0x0 0xba700000 0x0 0x00100000>,
				<0x0 0xba400000 0x0 0x00100000>, //ts0_sram_paddr
				<0x0 0xba060000 0x0 0x00050000>, //drv_devmng ts0_sysctl ipc2
				<0x0 0xb9c00000 0x0 0x00400000>, //ts1_doorbell_paddr
				<0x0 0xb9700000 0x0 0x00100000>,
				<0x0 0xb9400000 0x0 0x00020000>, //ts1_sram_paddr
				<0x0 0xb9060000 0x0 0x00050000>, // devdrv tsl_sysctl ipc3
				<0x0 0xab730000 0x0 0x0000b000>, //ipc7
				<0x0 0xab330000 0x0 0x0000b000>, //ipc6
				<0x0 0xaa000000 0x0 0x00040000>, //smmu1_camera
				<0x0 0xa9730000 0x0 0x0000b000>, //ipc5
				<0x0 0xa9330000 0x0 0x0000b000>, //ipc4
				<0x0 0xa80f0000 0x0 0x00001000>, //gpio8
				<0x0 0xa8000000 0x0 0x00040000>, //smmu0_camera
				<0x0 0xa5300000 0x0 0x00010000>, //ethernet nic

				//mttcan
				<0x0 0xA4600000 0x0 0x00001000>,
				<0x0 0xA4601000 0x0 0x00001000>,
				<0x0 0xA4610000 0x0 0x00001000>,
				<0x0 0xA4611000 0x0 0x00001000>,
				<0x0 0xA4620000 0x0 0x00001000>,
				<0x0 0xA4621000 0x0 0x00001000>,
				<0x0 0xA4630000 0x0 0x00001000>,
				<0x0 0xA4631000 0x0 0x00001000>,
				<0x0 0xA4640000 0x0 0x00001000>,
				<0x0 0xA4641000 0x0 0x00001000>,
				<0x0 0xA4650000 0x0 0x00001000>,
				<0x0 0xA4651000 0x0 0x00001000>,
				<0x0 0xA4660000 0x0 0x00001000>,
				<0x0 0xA4661000 0x0 0x00001000>,
				<0x0 0xA4670000 0x0 0x00001000>,
				<0x0 0xA4671000 0x0 0x00001000>,
				<0x0 0xA4680000 0x0 0x00001000>,
				<0x0 0xA4681000 0x0 0x00001000>,
				<0x0 0xA4690000 0x0 0x00001000>,
				<0x0 0xA4691000 0x0 0x00001000>,
				<0x0 0xA46A0000 0x0 0x00001000>,
				<0x0 0xA46A1000 0x0 0x00001000>,
				<0x0 0xA46B0000 0x0 0x00001000>,
				<0x0 0xA46B1000 0x0 0x00001000>,
				<0x0 0xA46D0000 0x0 0x00001000>,
				<0x0 0xA46D1000 0x0 0x00001000>,
				//mttcan

				<0x0 0xa4520000 0x0 0x00001000>, //gpio2
				<0x0 0xa4518000 0x0 0x00001000>, //mttcan0
				<0x0 0xa4500000 0x0 0x00001000>, //gpio0
				<0x0 0xa4100000 0x0 0x0000b000>, //ipc8
				<0x0 0xa40e0000 0x0 0x00010000>, //pcie p0_mbigen_peri_b
				<0x0 0xa4070000 0x0 0x00010000>, //virtio
				<0x0 0xa4000000 0x0 0x00040000>, //peri_smmu_controller1 ipc8
				<0x0 0xa2c00000 0x0 0x00200000>, //platform9
				<0x0 0xa2800000 0x0 0x00200000>, //platform
				<0x0 0x8b100000 0x0 0x00001000>, //gpio4
				<0x0 0x88000000 0x0 0x00040000>, //svm smmu_hac
				<0x0 0x84870000 0x0 0x0000B000>, //ipc1
				<0x0 0x840e0000 0x0 0x00001000>, //gpio5
				<0x0 0x804F0000 0x0 0x00010000>, //p0_mbigen_ao_b
				<0x0 0x80100000 0x0 0x00001000>, //ethernet mdio
				<0x0 0x80010000 0x0 0x00010000>, //ufs devdrv SYSCTL
				<0x0 0x2f900000 0x0 0x01e00000>, //blackbox_reserved rdr rdr_ddrdump_index rdr_lpm3_sram
				<0x0 0x2BB81000 0x0 0x00E00000>, //cq_uio_mem
				<0x0 0x2B700000 0x0 0x00400000>, //drv_log
				<0x0 0x29502000 0x0 0x001FF000>, //log_redirect
				<0x0 0x29500000 0x0 0x00001000>, //aicpu mailbox
				<0x0 0x28b00000 0x0 0x00010000>, //drv_hlt_device_profdrv_nodshell_test 46 0
				<0x0 0x28000000 0x0 0x00800000>, //drv_log GPA ERR
				<0x0 0x27200000 0x0 0x00100000>, //hlt profdrv test
				<0x0 0x26d00000 0x0 0x00200000>, //hlt profdrv test

				<0x0 0x0fb00000 0x0 0x01a93000>, //tsfw before random
				<0x0 0x11594000 0x0 0x1576c000>, //tsfw after random
				<0x0 0x0bb00000 0x0 0x04000000>, //devdrv sqcq
				<0x0 0x03e00000 0x0 0x00010000>, //GPA ERR
				<0x0 0x00A20000 0x0 0x00001000>, //tsensor_shm_paddr
				<0x0 0x009fe000 0x0 0x00003000>, //svm davinci_svm & aicpu / aicpufw_config_reserved davinci_svm
				<0x0 0x00000000 0x0 0x00900000>; //pcie

			map =	<0x1 0x100C0000 0x0 0x00010000>, //mntn rdr & devdrv
				<0x1 0x02060000 0x0 0x00010000>, //devdrv Dispatch
				<0x1 0x000E0000 0x0 0x00010000>, //devdrv FW
				<0x1 0x000a0000 0x0 0x00010000>, //dvpp_controler & devdrv MN
				<0x0 0xd7b00000 0x0 0x00100000>, //pcie
				<0x0 0xd7400000 0x0 0x00400000>, //pcie
				<0x0 0xcf090000 0x0 0x0000B000>, //ipc0
				<0x0 0xc9850000 0x0 0x00010000>, //dvpp_controller
				<0x0 0xc9800000 0x0 0x00040000>, //dvpp_controller
				<0x0 0xc9400000 0x0 0x00100000>, //dvpp venc0
				<0x0 0xc92ca000 0x0 0x00001000>, //dvpp jpegd0
				<0x0 0xc92c8000 0x0 0x00001000>, //dvpp jpege0
				<0x0 0xc92c2000 0x0 0x00002000>, //dvpp jpege0 jpegd0
				<0x0 0xc92c0000 0x0 0x00001000>, //dvpp jpege0 jpegd0
				<0x0 0xc9200000 0x0 0x00040000>, //dvpp vpc0 vpc-err
				<0x0 0xc9180000 0x0 0x00020000>, //dvpp vdec0
				<0x0 0xc90c0000 0x0 0x00010000>, //dvpp_controller
				<0x0 0xc9050000 0x0 0x00010000>, //dvpp_controller
				<0x0 0xc9000000 0x0 0x00040000>, //dvpp dsmmu0
				<0x0 0xc3300000 0x0 0x00040000>, //smmu smmu_ai9
				<0x0 0xc3100000 0x0 0x00040000>, //smmu smmu_ai8
				<0x0 0xc2f00000 0x0 0x00040000>, //smmu smmu_ai7
				<0x0 0xc2d00000 0x0 0x00040000>, //smmu smmu_ai6
				<0x0 0xc2b00000 0x0 0x00040000>, //smmu smmu_ai5
				<0x0 0xc2900000 0x0 0x00040000>, //smmu smmu_ai4
				<0x0 0xc2700000 0x0 0x00040000>, //smmu smmu_ai3
				<0x0 0xc2500000 0x0 0x00040000>, //smmu smmu_ai2
				<0x0 0xc2300000 0x0 0x00040000>, //smmu smmu_ai1
				<0x0 0xc2100000 0x0 0x00040000>, //smmu smmu_ai0
				<0x0 0xc1f00000 0x0 0x00040000>, //smmu smmu_aive7
				<0x0 0xc1d00000 0x0 0x00040000>, //smmu smmu_aive6
				<0x0 0xc1b00000 0x0 0x00040000>, //smmu smmu_aive5
				<0x0 0xc1900000 0x0 0x00040000>, //smmu smmu_aive4
				<0x0 0xc1700000 0x0 0x00040000>, //smmu smmu_aive3
				<0x0 0xc1500000 0x0 0x00040000>, //smmu smmu_aive2
				<0x0 0xc1300000 0x0 0x00040000>, //smmu smmu_aive1
				<0x0 0xc1100000 0x0 0x00040000>, //smmu smmu_aive0
				<0x0 0xbb000000 0x0 0x00040000>,
				<0x0 0xbac00000 0x0 0x00400000>, //ts0_doorbell_paddr
				<0x0 0xba700000 0x0 0x00100000>,
				<0x0 0xba400000 0x0 0x00100000>, //ts0_sram_paddr
				<0x0 0xba060000 0x0 0x00050000>, //drv_devmng ts0_sysctl ipc2
				<0x0 0xb9c00000 0x0 0x00400000>, //ts1_doorbell_paddr
				<0x0 0xb9700000 0x0 0x00100000>,
				<0x0 0xb9400000 0x0 0x00020000>, //ts1_sram_paddr
				<0x0 0xb9060000 0x0 0x00050000>, // devdrv tsl_sysctl ipc3
				<0x0 0xab730000 0x0 0x0000b000>, //ipc7
				<0x0 0xab330000 0x0 0x0000b000>, //ipc6
				<0x0 0xaa000000 0x0 0x00040000>, //smmu1_camera
				<0x0 0xa9730000 0x0 0x0000b000>, //ipc5
				<0x0 0xa9330000 0x0 0x0000b000>, //ipc4
				<0x0 0xa80f0000 0x0 0x00001000>, //gpio8
				<0x0 0xa8000000 0x0 0x00040000>, //smmu0_camera
				<0x0 0xa5300000 0x0 0x00010000>, //ethernet nic

				//mttcan
				<0x0 0xA4600000 0x0 0x00001000>,
				<0x0 0xA4601000 0x0 0x00001000>,
				<0x0 0xA4610000 0x0 0x00001000>,
				<0x0 0xA4611000 0x0 0x00001000>,
				<0x0 0xA4620000 0x0 0x00001000>,
				<0x0 0xA4621000 0x0 0x00001000>,
				<0x0 0xA4630000 0x0 0x00001000>,
				<0x0 0xA4631000 0x0 0x00001000>,
				<0x0 0xA4640000 0x0 0x00001000>,
				<0x0 0xA4641000 0x0 0x00001000>,
				<0x0 0xA4650000 0x0 0x00001000>,
				<0x0 0xA4651000 0x0 0x00001000>,
				<0x0 0xA4660000 0x0 0x00001000>,
				<0x0 0xA4661000 0x0 0x00001000>,
				<0x0 0xA4670000 0x0 0x00001000>,
				<0x0 0xA4671000 0x0 0x00001000>,
				<0x0 0xA4680000 0x0 0x00001000>,
				<0x0 0xA4681000 0x0 0x00001000>,
				<0x0 0xA4690000 0x0 0x00001000>,
				<0x0 0xA4691000 0x0 0x00001000>,
				<0x0 0xA46A0000 0x0 0x00001000>,
				<0x0 0xA46A1000 0x0 0x00001000>,
				<0x0 0xA46B0000 0x0 0x00001000>,
				<0x0 0xA46B1000 0x0 0x00001000>,
				<0x0 0xA46D0000 0x0 0x00001000>,
				<0x0 0xA46D1000 0x0 0x00001000>,
				//mttcan

				<0x0 0xa4520000 0x0 0x00001000>, //gpio2
				<0x0 0xa4518000 0x0 0x00001000>, //mttcan0
				<0x0 0xa4500000 0x0 0x00001000>, //gpio0
				<0x0 0xa4100000 0x0 0x0000b000>, //ipc8
				<0x0 0xa40e0000 0x0 0x00010000>, //pcie p0_mbigen_peri_b
				<0x0 0xa4070000 0x0 0x00010000>, //virtio
				<0x0 0xa4000000 0x0 0x00040000>, //peri_smmu_controller1 ipc8
				<0x0 0xa2c00000 0x0 0x00200000>, //platform
				<0x0 0xa2800000 0x0 0x00200000>, //platform
				<0x0 0x8b100000 0x0 0x00001000>, //gpio4
				<0x0 0x88000000 0x0 0x00040000>, //svm smmu_hac
				<0x0 0x84870000 0x0 0x0000B000>, //ipc1
				<0x0 0x840e0000 0x0 0x00001000>, //gpio5
				<0x0 0x804F0000 0x0 0x00010000>, //p0_mbigen_ao_b
				<0x0 0x80100000 0x0 0x00001000>, //ethernet mdio
				<0x0 0x80010000 0x0 0x00010000>, //ufs devdrv SYSCTL
				<0x0 0x2f900000 0x0 0x01e00000>, //blackbox_reserved rdr rdr_ddrdump_index rdr_lpm3_sram
				<0x0 0x2BB81000 0x0 0x00E00000>, //cq_uio_mem
				<0x0 0x2B700000 0x0 0x00400000>, //drv_log
				<0x0 0x29502000 0x0 0x001FF000>, //log_redirect
				<0x0 0x29500000 0x0 0x00001000>, //aicpu mailbox
				<0x0 0x28b00000 0x0 0x00010000>, //drv_hlt_device_profdrv_nodshell_test 46 0
				<0x0 0x28100000 0x0 0x00800000>, //drv_log
				<0x0 0x27200000 0x0 0x00100000>, //hlt profdrv test
				<0x0 0x26d00000 0x0 0x00200000>, //hlt profdrv test

				<0x0 0x0fb00000 0x0 0x01a93000>, //tsfw before random
				<0x0 0x11594000 0x0 0x1576c000>, //tsfw after random
				<0x0 0x0bb00000 0x0 0x04000000>, //devdrv sqcq
				<0x0 0x03e00000 0x0 0x00010000>,
				<0x0 0x00A20000 0x0 0x00001000>, //tsensor_shm_paddr
				<0x0 0x009fe000 0x0 0x00003000>, //svm davinci_svm & aicpu / aicpufw_config_reserved davinci_svm
				<0x0 0x00000000 0x0 0x00900000>; //pcie

			/* interrupt settings:
			 * 1st cell: real hardware irq number
			 * 2nd cell: interrupt config
			 *     bit [27:26]: Group setting
			 *     bit [24]: Trigger Type
			 *     bit [23:8]: Reserved
			 *     bit [7:0]: Priority
			 * 3rd cell: interrupt target config
			 *     Warning: Send to all cpus by default
			 */
			interrupts =	<32  0x010000E0 0xFFFFFFFF>, // llc
					<65  0x000000E0 0xFFFFFFFF>, // vpc
					<67  0x010000E0 0xFFFFFFFF>, // smmu
					<68  0x010000E0 0xFFFFFFFF>, // smmu
					<70  0x000000E0 0xFFFFFFFF>, // dvpp vpc0	<0    38 4>
					<71  0x000000E0 0xFFFFFFFF>, // dvpp vpc1	<0    39 4>
					<72  0x000000E0 0xFFFFFFFF>, // dvpp vpc2	<0    40 4>
					<73  0x000000E0 0xFFFFFFFF>, // dvpp vpc3	<0    41 4>
					<75  0x000000E0 0xFFFFFFFF>, // dvpp vpc0	<0    43 4>
					<76  0x000000E0 0xFFFFFFFF>, // dvpp vpc1	<0    44 4>
					<77  0x000000E0 0xFFFFFFFF>, // dvpp vpc2	<0    45 4>
					<78  0x000000E0 0xFFFFFFFF>, // dvpp vpc3	<0    46 4>
					<79  0x000000E0 0xFFFFFFFF>, // venc0 <0 47 4>
					<80  0x000000E0 0xFFFFFFFF>, // dvpp vpc0	<0    48 4>
					<81  0x000000E0 0xFFFFFFFF>, // dvpp vpc1	<0    49 4>
					<82  0x000000E0 0xFFFFFFFF>, // dvpp vpc2	<0    50 4>
					<83  0x000000E0 0xFFFFFFFF>, // dvpp vpc3	<0    51 4>
					<150 0x000000E0 0xFFFFFFFF>, // virtio		<0  0x76 4>

					<158 0x000000E0 0xFFFFFFFF>,//ipc mailbox	<0 126 4>
					<159 0x000000E0 0xFFFFFFFF>,//ipc mailbox	<0 127 4>
					<160 0x000000E0 0xFFFFFFFF>,//ipc mailbox	<0 128 4>
					<161 0x000000E0 0xFFFFFFFF>,//ipc mailbox	<0 129 4>
					<162 0x000000E0 0xFFFFFFFF>,//ipc mailbox	<0 130 4>
					<163 0x000000E0 0xFFFFFFFF>,//ipc mailbox	<0 131 4>
					<164 0x000000E0 0xFFFFFFFF>,//ipc mailbox	<0 132 4>
					<165 0x000000E0 0xFFFFFFFF>,//ipc mailbox	<0 133 4>

					<170 0x000000E0 0xFFFFFFFF>,//mttcan		<0 138 4>
					<171 0x000000E0 0xFFFFFFFF>,//mttcan		<0 139 4>
					<172 0x000000E0 0xFFFFFFFF>,//mttcan		<0 140 4>
					<174 0x000000E0 0xFFFFFFFF>,//mttcan		<0 142 4>
					<175 0x000000E0 0xFFFFFFFF>,//mttcan		<0 143 4>
					<176 0x000000E0 0xFFFFFFFF>,//mttcan		<0 144 4>
					<177 0x000000E0 0xFFFFFFFF>,//mttcan		<0 145 4>
					<178 0x000000E0 0xFFFFFFFF>,//mttcan		<0 146 4>
					<179 0x000000E0 0xFFFFFFFF>,//mttcan		<0 147 4>
					<180 0x000000E0 0xFFFFFFFF>,//mttcan		<0 148 4>
					<181 0x000000E0 0xFFFFFFFF>,//mttcan		<0 149 4>
					<183 0x000000E0 0xFFFFFFFF>,//mttcan		<0 151 4>
					<184 0x000000E0 0xFFFFFFFF>,//mttcan		<0 152 4>
					<185 0x000000E0 0xFFFFFFFF>,//mttcan		<0 153 4>
					<187 0x000000E0 0xFFFFFFFF>,//mttcan		<0 155 4>
					<190 0x000000E0 0xFFFFFFFF>,//mttcan		<0 158 4>
					<191 0x000000E0 0xFFFFFFFF>,//mttcan		<0 159 4>
					<195 0x000000E0 0xFFFFFFFF>,//sensorhub		<0 163 4>
					<196 0x000000E0 0xFFFFFFFF>,//sensorhub		<0 164 4>
					<210 0x000000E0 0xFFFFFFFF>,//ipc1 mailbox	<0 178 4>
					<211 0x000000E0 0xFFFFFFFF>,//ipc1 mailbox	<0 179 4>
					<212 0x000000E0 0xFFFFFFFF>,//ipc1 mailbox	<0 180 4>
					<213 0x000000E0 0xFFFFFFFF>,//ipc1 mailbox	<0 181 4>
					<221 0x000000E0 0xFFFFFFFF>,//ipc1 ACPU0	<0 189 4>
					<222 0x000000E0 0xFFFFFFFF>,//ipc1 ACPU1	<0 190 4>
					<223 0x000000E0 0xFFFFFFFF>,//ipc1 ACPU2	<0 191 4>
					<224 0x000000E0 0xFFFFFFFF>,//ipc1 ACPU3	<0 192 4>
					<225 0x000000E0 0xFFFFFFFF>,//ipc0 mailbox0	<0 193 4>
					<226 0x000000E0 0xFFFFFFFF>,//ipc0 ACPU0	<0 194 4>
					<230 0x000000E0 0xFFFFFFFF>,//devdrv ts-1	<0 0xC6 4>
					<234 0x000000E0 0xFFFFFFFF>,//ipc3 ACPU0 mailbox-5	<0 202 4>
					<235 0x000000E0 0xFFFFFFFF>,//ipc3 ACPU1 mailbox-6	<0 203 4>
					<236 0x000000E0 0xFFFFFFFF>,//ipc3 ACPU2 mailbox-7	<0 204 4>
					<237 0x000000E0 0xFFFFFFFF>,//ipc3 ACPU3 mailbox-8	<0 205 4>
					<245 0x000000E0 0xFFFFFFFF>,//aicpudrv 		<0 213 4>
					<247 0x000000E0 0xFFFFFFFF>,//devdrv ts-1	<0 0xD7 4>
					<252 0x000000E0 0xFFFFFFFF>,//devdrv ts-0	<0 0xDC 4>
					<256 0x000000E0 0xFFFFFFFF>,//ipc2 ACPU0 mailbox-5	<0 224 4>
					<257 0x000000E0 0xFFFFFFFF>,//ipc2 ACPU1 mailbox-6	<0 225 4>
					<258 0x000000E0 0xFFFFFFFF>,//ipc2 ACPU2 mailbox-7	<0 226 4>
					<259 0x000000E0 0xFFFFFFFF>,//ipc2 ACPU3 mailbox-8	<0 227 4>
					<267 0x000000E0 0xFFFFFFFF>,//aicpudrv		<0 235 4>
					<269 0x000000E0 0xFFFFFFFF>,//devdrv ts-0	<0 0xED 4>
					<275 0x000000E0 0xFFFFFFFF>,//ethernet		<0 243 4>
					<281 0x000000E0 0xFFFFFFFF>,//mttcan		<0 249 4>
					<282 0x000000E0 0xFFFFFFFF>,//mttcan		<0 250 4>
					<285 0x000000E0 0xFFFFFFFF>,//platform		<0 253 4>
					<286 0x000000E0 0xFFFFFFFF>,//platform		<0 254 4>
					<292 0x000000E0 0xFFFFFFFF>,//ipc0 mailbox-1	<0 260 4>
					<293 0x000000E0 0xFFFFFFFF>,//ipc0 ACPU1	<0 261 4>
					<296 0x000000E0 0xFFFFFFFF>,//ipc0 mailbox-2	<0 264 4>
					<297 0x000000E0 0xFFFFFFFF>,//ipc0 ACPU2	<0 265 4>
					<300 0x000000E0 0xFFFFFFFF>,//trusted_core	<0 268 4>
					<304 0x000000E0 0xFFFFFFFF>,//ipc4 mailbox-0	<0 272 4>
					<305 0x000000E0 0xFFFFFFFF>,//ipc4 mailbox-1	<0 273 4>
					<306 0x000000E0 0xFFFFFFFF>,//ipc4 mailbox-2	<0 274 4>
					<307 0x000000E0 0xFFFFFFFF>,//ipc5 mailbox-0	<0 275 4>
					<308 0x000000E0 0xFFFFFFFF>,//ipc5 mailbox-1	<0 276 4>
					<309 0x000000E0 0xFFFFFFFF>,//ipc5 mailbox-2	<0 277 4>
					<310 0x000000E0 0xFFFFFFFF>,//ipc4 ACPU		<0 278 4>
					<311 0x000000E0 0xFFFFFFFF>,//ipc5 ACPU		<0 279 4>
					<312 0x000000E0 0xFFFFFFFF>,//ipc0 mailbox-3	<0 280 4>
					<313 0x000000E0 0xFFFFFFFF>,//ipc0 ACPU3	<0 281 4>
					<320 0x000000E0 0xFFFFFFFF>,//ipc6 ACPU		<0 288 4>
					<321 0x000000E0 0xFFFFFFFF>,//ipc7 ACPU		<0 289 4>
					<323 0x000000E0 0xFFFFFFFF>,//devdrv ts-0	<0 0x123 4>
					<324 0x000000E0 0xFFFFFFFF>,//devdrv ts-1	<0 0x124 4>
					<331 0x000000E0 0xFFFFFFFF>,//ipc6 mailbox-0	<0 299 4>
					<332 0x000000E0 0xFFFFFFFF>,//ipc6 mailbox-1	<0 300 4>
					<333 0x000000E0 0xFFFFFFFF>,//ipc6 mailbox-2	<0 301 4>
					<334 0x000000E0 0xFFFFFFFF>,//ipc7 mailbox-0	<0 302 4>
					<335 0x000000E0 0xFFFFFFFF>,//ipc7 mailbox-1	<0 303 4>
					<336 0x000000E0 0xFFFFFFFF>,//ipc7 mailbox-2	<0 304 4>
					<401 0x000000E0 0xFFFFFFFF>, // dispatch	<0 0x173 4>
					<402 0x000000E0 0xFFFFFFFF>, // dvpp		<0 0x172 4>
					<403 0x000000E0 0xFFFFFFFF>, // dvpp		<0 0x173 4>
					<404 0x000000E0 0xFFFFFFFF>; // dvpp		<0 0x174 4>
		};

		xge_euler_shared {
			device-group = <0>;
			reg =	<0x0 0xa4510000 0x0 0x1000>;
			map =	<0x0 0xa4510000 0x0 0x1000>;
		};

		ufs {
			device-group = <0>;
			compatible = "udrv";
			interrupt-parent = <&gic>;
			reg = <0x0 0xa40c0000 0x0 0x00010000>,
			      <0x0 0xa4800000 0x0 0x00100000>,
			      <0x0 0xa4900000 0x0 0x00100000>;
			map = <0x0 0xa40c0000 0x0 0x00010000>,
			      <0x0 0xa4800000 0x0 0x00100000>,
			      <0x0 0xa4900000 0x0 0x00100000>;
			interrupts =	<142 0x000000E0 0xFFFFFFFF>, // ufs		<0  0x6E 4>
					<143 0x000000E0 0xFFFFFFFF>, // ufs		<0  0x6F 4>
					<144 0x000000E0 0xFFFFFFFF>; // ufs		<0  0x70 4>
		};

		xge_its_dev {
			device-group = <0>;
			msi-parent = <&its>;
			compatible = "udrv";
			interrupts = 	<0x7fab 0xff 0xE0 0>,//mbigen_gpio8
					<0x7fe4 0xff 0xE0 0>,//mbigen_xge
					<0x7fe4 0x36 0xE0 0>,//mbigen_xge
					<0x7fe4 0x37 0xE0 0>,//mbigen_xge
					<0x7fe4 0x38 0xE0 0>,//mbigen_xge
					<0x7fe4 0x39 0xE0 0>,//mbigen_xge
					<0x7fe4 0x00 0xE0 0>,//mbigen_xge
					<0x7fe4 0x08 0xE0 0>,//mbigen_xge
					<0x7fe4 0x3E 0xE0 0>;//mbigen_xge
			reg =	<0x0 0xa20f0000 0x0 0x10000>,
				<0x0 0xa4560000 0x0 0x00001000>,
				<0x0 0xcd000000 0x0 0x01000000>, //xge4567
				<0x0 0xa6022000 0x0 0x00001000>, //xge senserhub tsync_pps
				<0x0 0xa4710000 0x0 0x00001000>, //mdio_xge1
				<0x0 0xa4700000 0x0 0x00001000>, //mdio_xge0
				<0x0 0xa3000000 0x0 0x01000000>, //xge0123
				<0x0 0xa2e00000 0x0 0x00080000>, //xge01234567
				<0x0 0xa2240000 0x0 0x00002000>, //xge01234567
				<0x0 0xa20c0000 0x0 0x00006000>; //xge01234567
			map =	<0x0 0xa20f0000 0x0 0x10000>,
				<0x0 0xa4560000 0x0 0x00001000>,
				<0x0 0xcd000000 0x0 0x01000000>, //xge456
				<0x0 0xa6022000 0x0 0x00001000>, //xge senserhub tsync_pps
				<0x0 0xa4710000 0x0 0x00001000>, //mdio_xge1
				<0x0 0xa4700000 0x0 0x00001000>, //mdio_xge0
				<0x0 0xa3000000 0x0 0x01000000>, //xge0123
				<0x0 0xa2e00000 0x0 0x00080000>, //xge01234567
				<0x0 0xa2240000 0x0 0x00002000>, //xge01234567
				<0x0 0xa20c0000 0x0 0x00006000>; //xge01234567
		};

		android_spi {
			device-group = <0>;
			compatible = "udrv";
			interrupt-parent = <&gic>;
			reg =	<0x0 0x8b090000 0x0 0x00010000>,
				<0x0 0xfa6e0000 0x0 0x00001000>,
				<0x0 0x84020000 0x0 0x00001000>,
				<0x0 0x8b160000 0x0 0x00001000>,
				<0x0 0xcfc70000 0x0 0x00001000>,
				<0x0 0xa80e0000 0x0 0x00001000>,
				<0x0 0xa4490000 0x0 0x00010000>,
				<0x0 0xa44a0000 0x0 0x00010000>,
				<0x0 0xa44b0000 0x0 0x00010000>;
			map=	<0x0 0x8b090000 0x0 0x00010000>,
				<0x0 0xfa6e0000 0x0 0x00001000>,
				<0x0 0x84020000 0x0 0x00001000>,
				<0x0 0x8b160000 0x0 0x00001000>,
				<0x0 0xcfc70000 0x0 0x00001000>,
				<0x0 0xa80e0000 0x0 0x00001000>,
				<0x0 0xa4490000 0x0 0x00010000>,
				<0x0 0xa44a0000 0x0 0x00010000>,
				<0x0 0xa44b0000 0x0 0x00010000>;
			interrupts =	<173 0x000000E0 0xFFFFFFFF>,
					<186 0x000000E0 0xFFFFFFFF>,
					<188 0x000000E0 0xFFFFFFFF>,
					<189 0x000000E0 0xFFFFFFFF>;
		};
	};

	/* See Documentation/dts-gic.md for interrupts and distributor_config */
	gic: interrupt-controller@85000000 {
		compatible = "arm,gic-v3";

		#address-cells = <2>;
		#size-cells = <2>;

		/* Enable group 0, Group1NS, Group1S, ARE_NS, ARE_S,
		 * Split EOI and Deactive Mode */
		distributor-config = <0x80000037>;

		#interrupt-cells = <3>;
		#redistributor-regions = <1>;
		redistributor-stride = <0x20000>;
		interrupt-controller;

		reg =	<0x0 0x85000000 0x0 0x10000>,	/* GICD */
			<0x0 0x85100000 0x0 0x800000>;	/* GICR */
		alignment = <0x100000 0x100000>;

		interrupts = <25 0x000000E0 0xFFFFFFFF>;

		/* We haven't support this */
		its: interrupt-controller@87000000 {
			compatible = "arm,gic-v3-its";
			msi-controller;
			reg = <0x0 0x87000000 0x0 0x40000>;
			alignment = <0x100000>;
			#interrupt-cells = <4>;
		};
	};

	ipi {
		/* smp ipi */
		compatible = "arm,smp-ipi";

		interrupt-parent = <&gic>;

		interrupts =	<0 0x00000060 0xFFFFFFFF>, /* IPI_RESCHEDULE */
				<1 0x00000060 0xFFFFFFFF>; /* IPI_CALL_FUNC */
	};

	/* used to debug its driver */
	debug_dev0:dev_debug@0 {
		compatible = "arm,gic-its-debug0";
		interrupts =	<0x245 0 0xE0 0>,
				<0x245 7 0xE0 0>,
				<0x245 14 0xE0 0>,
				<0x245 23 0xE0 0>;
		msi-parent = <&its>;
	};

	kev {
		compatible = "huawei,kev-trace";

		memory {
			type = <0x0>;
			ring-buffer-count = <0x3>;
			ring-buffer-sizes = <0x1000 0x20000 0x1000>;
		};
		kev_sample {
			config = <0x2>;
			enable = <0x1>;
		};
		kev_klog {
			enable = <0x1>;
		};
		kev_fiq {
			config = <0x4>;
			enable = <0x1>;
		};
	};

	hm-udrv {
		compatible = "udrv";
		reg = <0x0 0x840c0000 0x0 0x10000>,
		      <0x9 0x10000000 0x0 0x80000000>,
		      <0x9 0x00000000 0x0 0x0FFF0000>,
		      <0x0 0x0B101000 0x0 0x001FF000>,
		      <0x0 0x61E00000 0x0 0x10000000>,
		      <0xA 0x00000000 0x0 0x0FFF0000>,
		      <0xA 0x10000000 0x1 0xf0000000>,
		      <0x0 0xA4510000 0x0 0x1000>,
		      <0x0 0x80000000 0x0 0x10000>,
		      <0x0 0x840f0000 0x0 0x10000>,
		      <0x0 0xfa6b0000 0x0 0x10000>,
		      <0x0 0xfa6f0000 0x0 0x10000>;
		};
	security {
		trusted_boot = "disabled";
	};
	};

	soc {
		compatible = "simple-bus";
		#address-cells = <2>;
		#size-cells = <2>;
		ranges;

		uart0: uart@840c0000 {
			compatible = "arm,pl011", "arm,pl011,uart";
			reg = <0x0 0x840c0000 0x0 0x10000>;
			alignment = <0x1000>;

			/* kernel control input */
			kernel-input;

			interrupt-parent=<&gic>;
			interrupts=<359 0x00000060 0x00000001>;
		};

		/* TODO: the timer is only for single core system. The smp system
		 * is not supported
		 * Thers is no kernel tick field here. This node is just for the
		 * user-space timer to probe.
		 */
		arm_generic_timer: generic_timer {
			compatible = "arm,armv8-generic-timer";
			clock-frequency = <10000000>;

			/* interrupt settings */
			interrupt-parent = <&gic>;

			/* PPI 30: Non-secure physical timer
			 * level triggered, only cpu0, hwprio:0x60 */
			interrupts = <30 0x00000060 0x00000001>;
		};
	};

	/* Bios would check the bootargs in dt.img.
	 * Just add bootargs to pass verification of bios.
	 * and now, this bootargs is not used in hongmeng.
	 */
	chosen {
		bootargs = "console=ttyAMA0,115200 rdinit=/sbin/init syslog earlycon=pl011,mmio32,0x840c0000 initrd=0x880002000,450M  log_redirect=0x1fc000@0xb101000 cma=256M default_hugepagesz=2M";//for debug ethernet acpi = off
	};

};
